# LPC11E6x register map
File version: 0.8
CPU: CM0PLUS r0p1, little endian, no MPU, no FPU, 0x2 interrupt priority bits, 0x0 interrupts
Registers are 32-bit, read-write, reset 0x0 unless marked. A register's access mark holds for its fields unless they carry their own. Offsets are from the block's base; [hi:lo] are bit positions; {n}, {i} and the like mark numbered series.

## CRC — Cyclic Redundancy Check (CRC) engine
Base 0x50000000
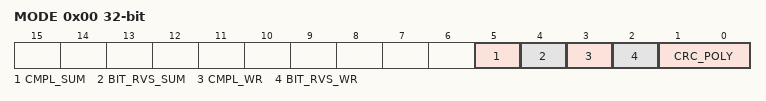
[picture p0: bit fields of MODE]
0x00 MODE — CRC mode register
  [5] CMPL_SUM — CRC sum complement: 1= 1's complement for CRC_SUM 0=No 1's complement for CRC_SUM
  [4] BIT_RVS_SUM — CRC sum bit order: 1= Bit order reverse for CRC_SUM 0= No bit order reverse for CRC_SUM
  [3] CMPL_WR — Data complement: 1= 1's complement for CRC_WR_DATA 0= No 1's complement for CRC_WR_DATA
  [2] BIT_RVS_WR — Data bit order: 1= Bit order reverse for CRC_WR_DATA (per byte) 0= No bit order reverse for CRC_WR_DATA (per byte)
  [1:0] CRC_POLY — CRC polynom: 1X= CRC-32 polynomial 01= CRC-16 polynomial 00= CRC-CCITT polynomial
0x04 SEED reset 0xFFFF — CRC seed register
  [31:0] CRC_SEED — A write access to this register will load CRC seed value to CRC_SUM register with selected bit order and 1's complement pre-processes. A write access to this register will overrule the CRC calculation in progresses.
0x08 SUM ro reset 0xFFFF — CRC checksum register
  [31:0] CRC_SUM — The most recent CRC sum can be read through this register with selected bit order and 1's complement post-processes.
0x08 WR_DATA wo reset not defined — CRC data register
  [31:0] CRC_WR_DATA — Data written to this register will be taken to perform CRC calculation with selected bit order and 1's complement pre-process. Any write size 8, 16 or 32-bit are allowed and accept back-to-back transactions.

## GPIO_PORT — General Purpose I/O (GPIO)
Base 0xA0000000
{0x0+i} B[{i}] 8-bit reset not defined (i=0..87) — Byte pin registers
  [0] PBYTE — Read: state of the pin PIOm_n, regardless of direction, masking, or alternate function, except that pins configured as analog I/O always read as 0. One register for each port pin: m = port 0 to 2; n = pin 0 to 31 for port 0 and 1 and pin 0 to 11 for port 2. Write: loads the pin's output bit.
{0x1000+4i} W[{i}] reset not defined (i=0..87) — Word pin registers
  [31:0] PWORD — Read 0: pin PIOm_n is LOW. Write 0: clear output bit. Read 0xFFFF FFFF: pin PIOm_n is HIGH. Write any value 0x0000 0001 to 0xFFFF FFFF: set output bit. Only 0 or 0xFFFF FFFF can be read. Writing any value other than 0 will set the output bit. One register for each port pin: m = port 0 to 2; n = pin 0 to 31 for port 0 and 1 and pin 0 to 11 for port2.
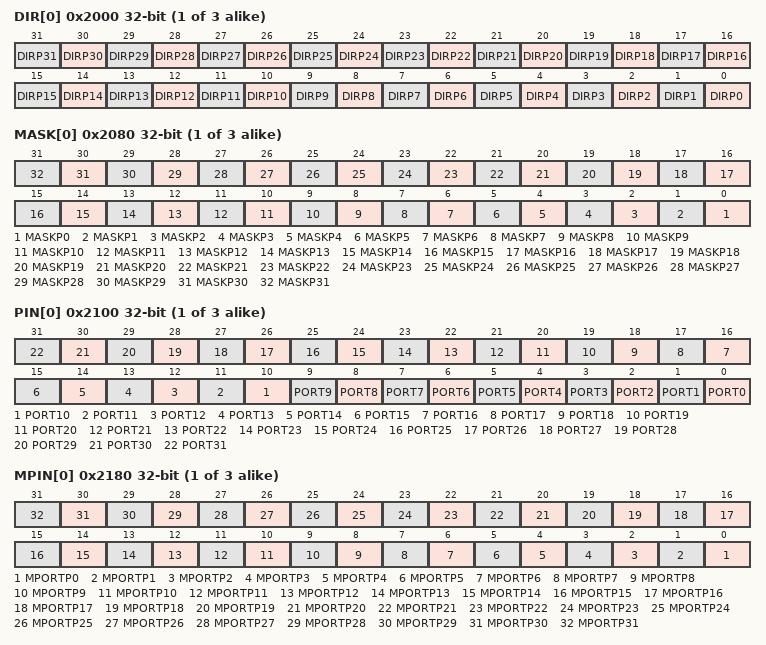
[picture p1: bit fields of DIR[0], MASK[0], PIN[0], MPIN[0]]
{0x2000+4i} DIR[{i}] (i=0..2) — Port Direction registers
  [n] DIRP{n} (n=0..31) — Selects pin direction for pin PIOm_n (bit 0 = PIOm_0, bit 1 = PIOm_1, ..., bit 31 = PIOm_31). m = port 0 to 2; n = pin 0 to 31 for port 0 and 1 and pin 0 to 11 for port2. 0 = input. 1 = output.
{0x2080+4i} MASK[{i}] (i=0..2) — Port Mask register
  [n] MASKP{n} (n=0..31) — Controls which bits corresponding to PIOm_n are active in the MPORT register (bit 0 = PIOm_0, bit 1 = PIOm_1, ..., bit 31 = PIOm_31). m = port 0 to 2; n = pin 0 to 31 for port 0 and 1 and pin 0 to 11 for port2. 0 = Read MPORT: pin state; write MPORT: load output bit. 1 = Read MPORT: 0; write MPORT: output bit not affected.
{0x2100+4i} PIN[{i}] reset not defined (i=0..2) — Port pin register
  [n] PORT{n} (n=0..31) — Reads pin states or loads output bits (bit 0 = PIOm_0, bit 1 = PIOm_1, ..., bit 31 = PIOm_31). m = port 0 to 2; n = pin 0 to 31 for port 0 and 1 and pin 0 to 11 for port2. 0 = Read: pin is low; write: clear output bit. 1 = Read: pin is high; write: set output bit.
{0x2180+4i} MPIN[{i}] reset not defined (i=0..2) — Masked port register
  [n] MPORTP{n} (n=0..31) — Masked port register (bit 0 = PIOm_0, bit 1 =PIOm_1, ..., bit 31 = PIOm_31). m = port 0 to 2; n = pin 0 to 31 for port 0 and 1 and pin 0 to 11 for port2. 0 = Read: pin is LOW and/or the corresponding bit in the MASK register is 1; write: clear output bit if the corresponding bit in the MASK register is 0. 1 = Read: pin is HIGH and the corresponding bit in the MASK register is 0; write: set output bit if the corresponding bit in the MASK register is 0.
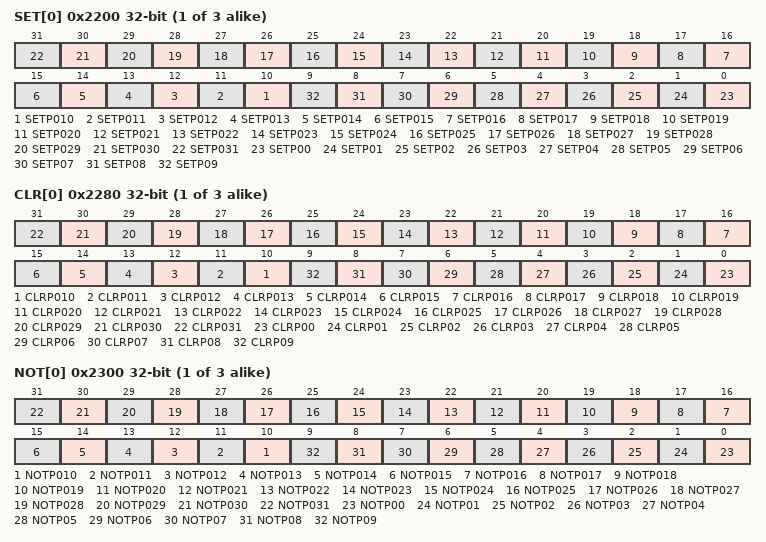
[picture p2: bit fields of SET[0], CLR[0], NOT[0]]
{0x2200+4i} SET[{i}] (i=0..2) — Write: Set port register Read: port output bits
  [n] SETP{n:03} (n=10..31) — Read or set output bits. 0 = Read: output bit: write: no operation. 1 = Read: output bit; write: set output bit.
  [n] SETP{n:02} (n=0..9) — Read or set output bits. 0 = Read: output bit: write: no operation. 1 = Read: output bit; write: set output bit.
{0x2280+4i} CLR[{i}] wo reset not defined (i=0..2) — Clear port
  [n] CLRP{n:03} (n=10..31) — Clear output bits: 0 = No operation. 1 = Clear output bit.
  [n] CLRP{n:02} (n=0..9) — Clear output bits: 0 = No operation. 1 = Clear output bit.
{0x2300+4i} NOT[{i}] wo reset not defined (i=0..2) — Toggle port
  [n] NOTP{n:03} (n=10..31) — Toggle output bits: 0 = no operation. 1 = Toggle output bit.
  [n] NOTP{n:02} (n=0..9) — Toggle output bits: 0 = no operation. 1 = Toggle output bit.
